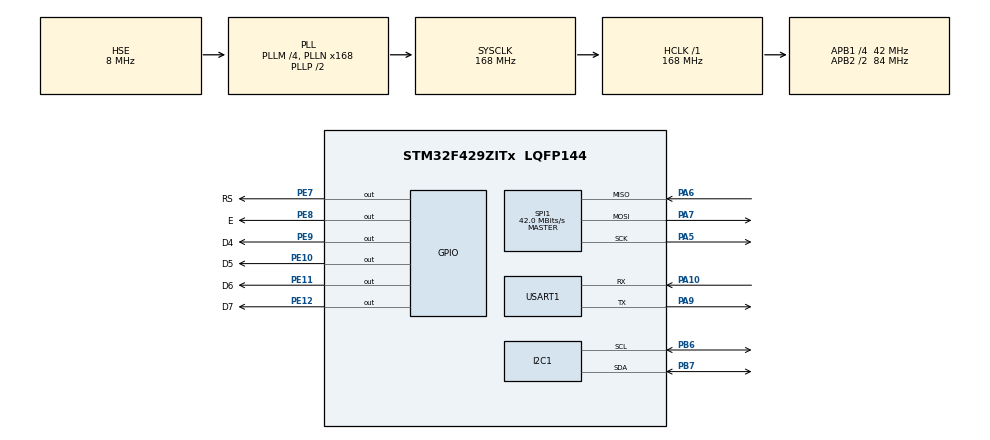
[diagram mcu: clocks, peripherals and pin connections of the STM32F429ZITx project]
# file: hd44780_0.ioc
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Mcu.Family=STM32F4
Mcu.Name=STM32F429ZITx
Mcu.Package=LQFP144
NVIC.I2C1_EV_IRQn=true\:0\:0\:false\:false\:true\:true\:true
NVIC.PriorityGroup=NVIC_PRIORITYGROUP_4
NVIC.USART1_IRQn=true\:0\:0\:false\:false\:true\:true\:true
PA10.Mode=Asynchronous
PA10.Signal=USART1_RX
PA5.Mode=Full_Duplex_Master
PA5.Signal=SPI1_SCK
PA6.Mode=Full_Duplex_Master
PA6.Signal=SPI1_MISO
PA7.Mode=Full_Duplex_Master
PA7.Signal=SPI1_MOSI
PA9.Mode=Asynchronous
PA9.Signal=USART1_TX
PB6.Mode=I2C
PB6.Signal=I2C1_SCL
PB7.Mode=I2C
PB7.Signal=I2C1_SDA
PE10.GPIO_Label=D5
PE10.Signal=GPIO_Output
PE11.GPIO_Label=D6
PE11.Signal=GPIO_Output
PE12.GPIO_Label=D7
PE12.Signal=GPIO_Output
PE7.GPIO_Label=RS
PE7.Signal=GPIO_Output
PE8.GPIO_Label=E
PE8.Signal=GPIO_Output
PE9.GPIO_Label=D4
PE9.Signal=GPIO_Output
PH0/OSC_IN.Mode=HSE-External-Oscillator
PH0/OSC_IN.Signal=RCC_OSC_IN
PH1/OSC_OUT.Mode=HSE-External-Oscillator
PH1/OSC_OUT.Signal=RCC_OSC_OUT
ProjectManager.HeapSize=0x200
ProjectManager.StackSize=0x400
ProjectManager.TargetToolchain=STM32CubeIDE
RCC.48MHZClocksFreq_Value=84000000
RCC.AHBFreq_Value=168000000
RCC.APB1CLKDivider=RCC_HCLK_DIV4
RCC.APB1Freq_Value=42000000
RCC.APB1TimFreq_Value=84000000
RCC.APB2CLKDivider=RCC_HCLK_DIV2
RCC.APB2Freq_Value=84000000
RCC.APB2TimFreq_Value=168000000
RCC.CortexFreq_Value=168000000
RCC.HCLKFreq_Value=168000000
RCC.HSE_VALUE=8000000
RCC.HSI_VALUE=16000000
RCC.LSE_VALUE=32768
RCC.PLLM=4
RCC.PLLN=168
RCC.PLLSourceVirtual=RCC_PLLSOURCE_HSE
RCC.SYSCLKFreq_VALUE=168000000
RCC.SYSCLKSource=RCC_SYSCLKSOURCE_PLLCLK
RCC.VCOOutputFreq_Value=336000000
SPI1.CalculateBaudRate=42.0 MBits/s
SPI1.Direction=SPI_DIRECTION_2LINES
SPI1.Mode=SPI_MODE_MASTER
SPI1.VirtualType=VM_MASTER
USART1.VirtualMode=VM_ASYNC
board=custom

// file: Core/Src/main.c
/* USER CODE BEGIN Header */
/**
  ******************************************************************************
  * @file           : main.c
  * @brief          : Main program body
  ******************************************************************************
  * @attention
  *
  * <h2><center>&copy; Copyright (c) 2019 STMicroelectronics.
  * All rights reserved.</center></h2>
  *
  * This software component is licensed by ST under BSD 3-Clause license,
  * the "License"; You may not use this file except in compliance with the
  * License. You may obtain a copy of the License at:
  *                        opensource.org/licenses/BSD-3-Clause
  *
  ******************************************************************************
  */
/* USER CODE END Header */

#include "main.h"

/* USER CODE BEGIN Includes */
#include "tm_stm32_hd44780.h"
/* USER CODE END Includes */

I2C_HandleTypeDef hi2c1;

SPI_HandleTypeDef hspi1;

UART_HandleTypeDef huart1;

/* USER CODE BEGIN PV */
uint8_t cols=16;
uint8_t rows=2;

uint8_t top[16];
uint8_t btm[16];
/* USER CODE END PV */

void SystemClock_Config(void);
static void MX_GPIO_Init(void);
static void MX_I2C1_Init(void);
static void MX_SPI1_Init(void);
static void MX_USART1_UART_Init(void);

int main(void)
{

  /* MCU Configuration--------------------------------------------------------*/

  /* Reset of all peripherals, Initializes the Flash interface and the Systick. */
  HAL_Init();

  /* Configure the system clock */
  SystemClock_Config();

  /* Initialize all configured peripherals */
  MX_GPIO_Init();
  MX_I2C1_Init();
  MX_SPI1_Init();
  MX_USART1_UART_Init();

  /* USER CODE BEGIN 2 */

  TM_HD44780_Init(cols, rows);
  sprintf(top,"0123456789");
  sprintf(btm,"987654321");
//  TM_HD44780_BlinkOn();
  TM_HD44780_CursorOn();
  /* USER CODE END 2 */

  /* Infinite loop */
  while (1)
  {

    /* USER CODE BEGIN 3 */
	  TM_HD44780_Puts(0, 0, top);
	  TM_HD44780_Puts(0, 1, btm);
  }
  /* USER CODE END 3 */
}

void SystemClock_Config(void)
{
  RCC_OscInitTypeDef RCC_OscInitStruct = {0};
  RCC_ClkInitTypeDef RCC_ClkInitStruct = {0};

  /** Configure the main internal regulator output voltage
  */
  __HAL_RCC_PWR_CLK_ENABLE();
  __HAL_PWR_VOLTAGESCALING_CONFIG(PWR_REGULATOR_VOLTAGE_SCALE1);
  /** Initializes the CPU, AHB and APB busses clocks
  */
  RCC_OscInitStruct.OscillatorType = RCC_OSCILLATORTYPE_HSE;
  RCC_OscInitStruct.HSEState = RCC_HSE_ON;
  RCC_OscInitStruct.PLL.PLLState = RCC_PLL_ON;
  RCC_OscInitStruct.PLL.PLLSource = RCC_PLLSOURCE_HSE;
  RCC_OscInitStruct.PLL.PLLM = 4;
  RCC_OscInitStruct.PLL.PLLN = 168;
  RCC_OscInitStruct.PLL.PLLP = RCC_PLLP_DIV2;
  RCC_OscInitStruct.PLL.PLLQ = 4;
  if (HAL_RCC_OscConfig(&RCC_OscInitStruct) != HAL_OK)
  {
    Error_Handler();
  }
  /** Initializes the CPU, AHB and APB busses clocks
  */
  RCC_ClkInitStruct.ClockType = RCC_CLOCKTYPE_HCLK|RCC_CLOCKTYPE_SYSCLK
                              |RCC_CLOCKTYPE_PCLK1|RCC_CLOCKTYPE_PCLK2;
  RCC_ClkInitStruct.SYSCLKSource = RCC_SYSCLKSOURCE_PLLCLK;
  RCC_ClkInitStruct.AHBCLKDivider = RCC_SYSCLK_DIV1;
  RCC_ClkInitStruct.APB1CLKDivider = RCC_HCLK_DIV4;
  RCC_ClkInitStruct.APB2CLKDivider = RCC_HCLK_DIV2;

  if (HAL_RCC_ClockConfig(&RCC_ClkInitStruct, FLASH_LATENCY_5) != HAL_OK)
  {
    Error_Handler();
  }
}

static void MX_I2C1_Init(void)
{

  hi2c1.Instance = I2C1;
  hi2c1.Init.ClockSpeed = 100000;
  hi2c1.Init.DutyCycle = I2C_DUTYCYCLE_2;
  hi2c1.Init.OwnAddress1 = 0;
  hi2c1.Init.AddressingMode = I2C_ADDRESSINGMODE_7BIT;
  hi2c1.Init.DualAddressMode = I2C_DUALADDRESS_DISABLE;
  hi2c1.Init.OwnAddress2 = 0;
  hi2c1.Init.GeneralCallMode = I2C_GENERALCALL_DISABLE;
  hi2c1.Init.NoStretchMode = I2C_NOSTRETCH_DISABLE;
  if (HAL_I2C_Init(&hi2c1) != HAL_OK)
  {
    Error_Handler();
  }
  /** Configure Analogue filter
  */
  if (HAL_I2CEx_ConfigAnalogFilter(&hi2c1, I2C_ANALOGFILTER_ENABLE) != HAL_OK)
  {
    Error_Handler();
  }
  /** Configure Digital filter
  */
  if (HAL_I2CEx_ConfigDigitalFilter(&hi2c1, 0) != HAL_OK)
  {
    Error_Handler();
  }

}

static void MX_SPI1_Init(void)
{

  /* SPI1 parameter configuration*/
  hspi1.Instance = SPI1;
  hspi1.Init.Mode = SPI_MODE_MASTER;
  hspi1.Init.Direction = SPI_DIRECTION_2LINES;
  hspi1.Init.DataSize = SPI_DATASIZE_8BIT;
  hspi1.Init.CLKPolarity = SPI_POLARITY_LOW;
  hspi1.Init.CLKPhase = SPI_PHASE_1EDGE;
  hspi1.Init.NSS = SPI_NSS_SOFT;
  hspi1.Init.BaudRatePrescaler = SPI_BAUDRATEPRESCALER_2;
  hspi1.Init.FirstBit = SPI_FIRSTBIT_MSB;
  hspi1.Init.TIMode = SPI_TIMODE_DISABLE;
  hspi1.Init.CRCCalculation = SPI_CRCCALCULATION_DISABLE;
  hspi1.Init.CRCPolynomial = 10;
  if (HAL_SPI_Init(&hspi1) != HAL_OK)
  {
    Error_Handler();
  }

}

static void MX_USART1_UART_Init(void)
{

  huart1.Instance = USART1;
  huart1.Init.BaudRate = 115200;
  huart1.Init.WordLength = UART_WORDLENGTH_8B;
  huart1.Init.StopBits = UART_STOPBITS_1;
  huart1.Init.Parity = UART_PARITY_NONE;
  huart1.Init.Mode = UART_MODE_TX_RX;
  huart1.Init.HwFlowCtl = UART_HWCONTROL_NONE;
  huart1.Init.OverSampling = UART_OVERSAMPLING_16;
  if (HAL_UART_Init(&huart1) != HAL_OK)
  {
    Error_Handler();
  }

}

static void MX_GPIO_Init(void)
{
  GPIO_InitTypeDef GPIO_InitStruct = {0};

  /* GPIO Ports Clock Enable */
  __HAL_RCC_GPIOH_CLK_ENABLE();
  __HAL_RCC_GPIOA_CLK_ENABLE();
  __HAL_RCC_GPIOE_CLK_ENABLE();
  __HAL_RCC_GPIOB_CLK_ENABLE();

  /*Configure GPIO pin Output Level */
  HAL_GPIO_WritePin(GPIOE, RS_Pin|E_Pin|D4_Pin|D5_Pin
                          |D6_Pin|D7_Pin, GPIO_PIN_RESET);

  /*Configure GPIO pins : RS_Pin E_Pin D4_Pin D5_Pin
                           D6_Pin D7_Pin */
  GPIO_InitStruct.Pin = RS_Pin|E_Pin|D4_Pin|D5_Pin
                          |D6_Pin|D7_Pin;
  GPIO_InitStruct.Mode = GPIO_MODE_OUTPUT_PP;
  GPIO_InitStruct.Pull = GPIO_NOPULL;
  GPIO_InitStruct.Speed = GPIO_SPEED_FREQ_LOW;
  HAL_GPIO_Init(GPIOE, &GPIO_InitStruct);

}

void Error_Handler(void)
{
}

/************************ (C) COPYRIGHT STMicroelectronics *****END OF FILE****/
